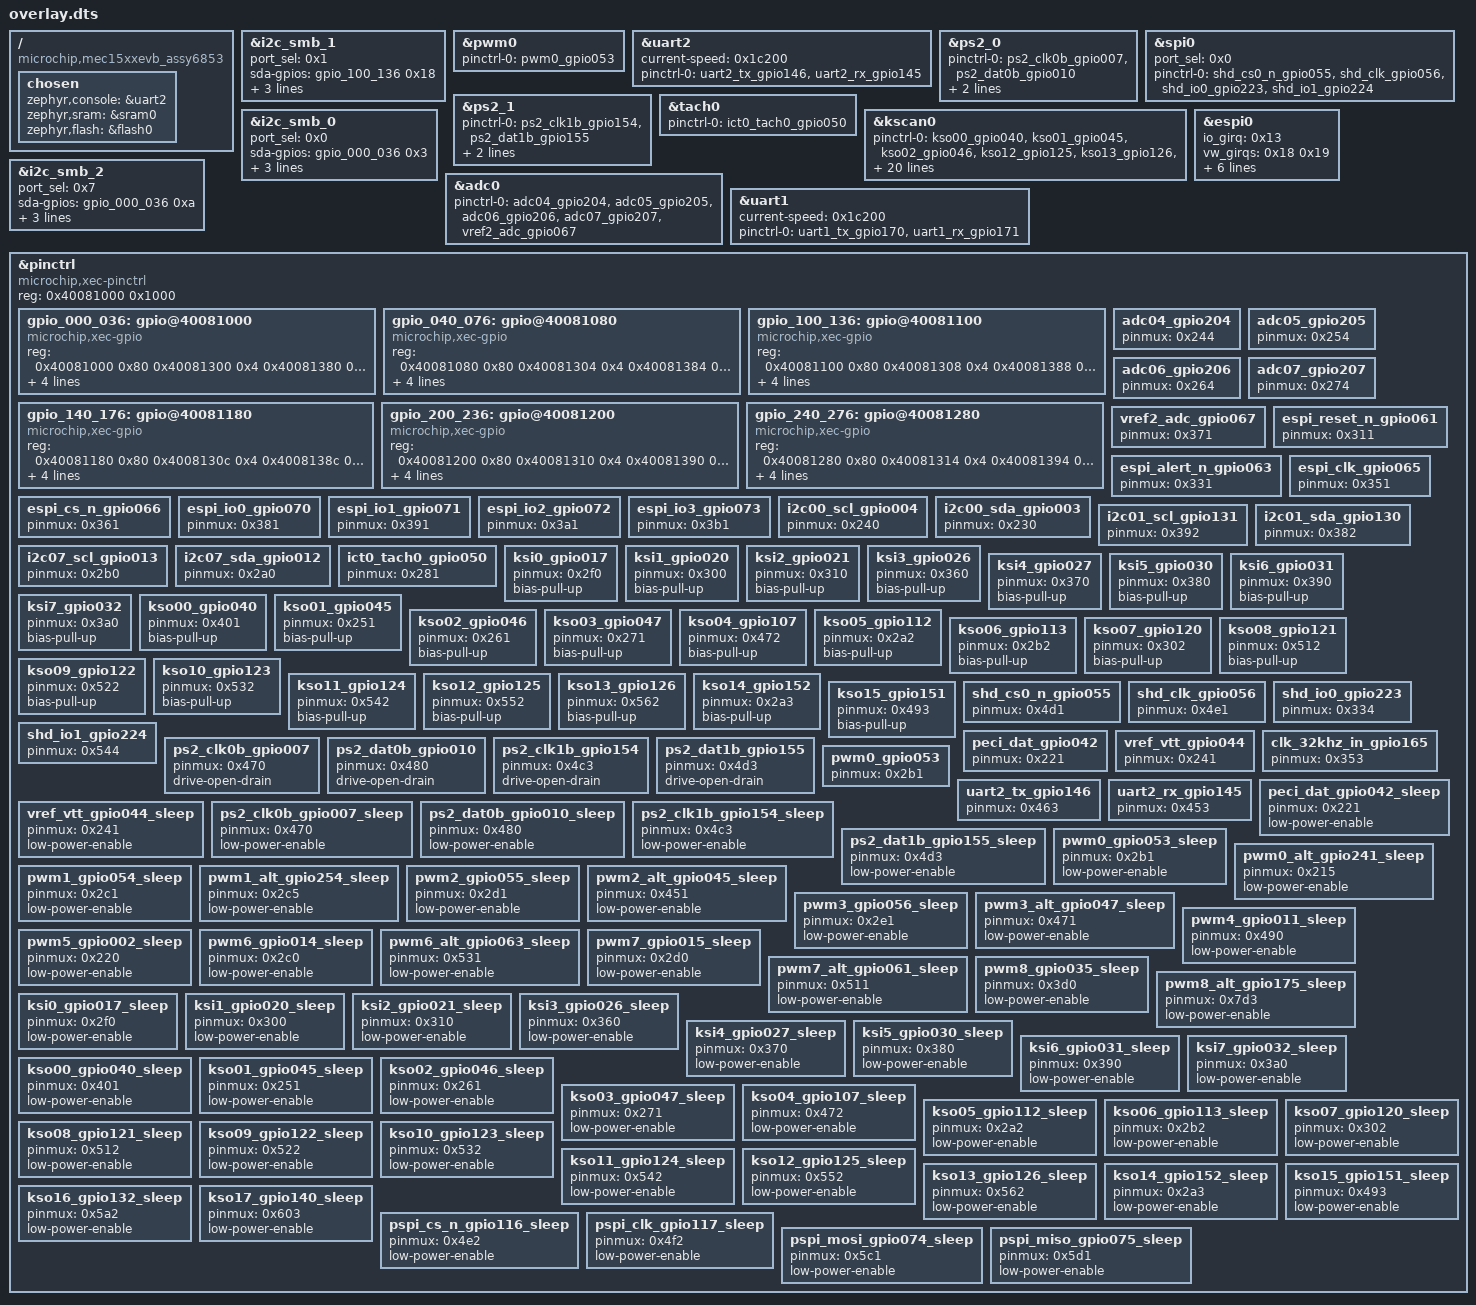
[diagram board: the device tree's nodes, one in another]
/ {
	compatible = "microchip,mec15xxevb_assy6853", "microchip,mec1501hsz";
	chosen {
		zephyr,console = &uart2;
		zephyr,sram = &sram0;
		zephyr,flash = &flash0;
	};
};
&i2c_smb_1{
	status = "okay";
	port_sel = < 0x1 >;
	sda-gpios = < &gpio_100_136 0x18 0x0 >;
	scl-gpios = < &gpio_100_136 0x19 0x0 >;
	pinctrl-0 = < &i2c01_scl_gpio131 &i2c01_sda_gpio130 >;
	pinctrl-names = "default";
};
&pwm0{
	status = "okay";
	pinctrl-0 = < &pwm0_gpio053 >;
	pinctrl-names = "default";
};
&uart2{
	current-speed = < 0x1c200 >;
	status = "okay";
	pinctrl-0 = < &uart2_tx_gpio146 &uart2_rx_gpio145 >;
	pinctrl-names = "default";
};
&ps2_0{
	status = "okay";
	pinctrl-0 = < &ps2_clk0b_gpio007 &ps2_dat0b_gpio010 >;
	pinctrl-1 = < &ps2_clk0b_gpio007_sleep &ps2_dat0b_gpio010_sleep >;
	pinctrl-names = "default", "sleep";
};
&spi0{
	status = "okay";
	port_sel = < 0x0 >;
	pinctrl-0 = < &shd_cs0_n_gpio055 &shd_clk_gpio056 &shd_io0_gpio223 &shd_io1_gpio224 >;
	pinctrl-names = "default";
};
&ps2_1{
	status = "okay";
	pinctrl-0 = < &ps2_clk1b_gpio154 &ps2_dat1b_gpio155 >;
	pinctrl-1 = < &ps2_clk1b_gpio154_sleep &ps2_dat1b_gpio155_sleep >;
	pinctrl-names = "default", "sleep";
};
&tach0{
	status = "okay";
	pinctrl-0 = < &ict0_tach0_gpio050 >;
	pinctrl-names = "default";
};
&i2c_smb_0{
	status = "okay";
	port_sel = < 0x0 >;
	sda-gpios = < &gpio_000_036 0x3 0x0 >;
	scl-gpios = < &gpio_000_036 0x4 0x0 >;
	pinctrl-0 = < &i2c00_scl_gpio004 &i2c00_sda_gpio003 >;
	pinctrl-names = "default";
};
&kscan0{
	status = "okay";
	pinctrl-0 = < &kso00_gpio040 &kso01_gpio045 &kso02_gpio046 &kso12_gpio125 &kso13_gpio126 &kso03_gpio047 &kso04_gpio107 &kso05_gpio112 &kso06_gpio113 &kso14_gpio152 &kso15_gpio151 &kso07_gpio120 &kso08_gpio121 &kso09_gpio122 &kso10_gpio123 &kso11_gpio124 &ksi0_gpio017 &ksi1_gpio020 &ksi2_gpio021 &ksi3_gpio026 &ksi4_gpio027 &ksi5_gpio030 &ksi6_gpio031 &ksi7_gpio032 >;
	pinctrl-1 = < &kso00_gpio040_sleep &kso01_gpio045_sleep &kso02_gpio046_sleep &kso12_gpio125_sleep &kso13_gpio126_sleep &kso03_gpio047_sleep &kso04_gpio107_sleep &kso05_gpio112_sleep &kso06_gpio113_sleep &kso14_gpio152_sleep &kso15_gpio151_sleep &kso07_gpio120_sleep &kso08_gpio121_sleep &kso09_gpio122_sleep &kso10_gpio123_sleep &kso11_gpio124_sleep &ksi0_gpio017_sleep &ksi1_gpio020_sleep &ksi2_gpio021_sleep &ksi3_gpio026_sleep &ksi4_gpio027_sleep &ksi5_gpio030_sleep &ksi6_gpio031_sleep &ksi7_gpio032_sleep >;
	pinctrl-names = "default", "sleep";
};
&espi0{
	status = "okay";
	io_girq = < 0x13 >;
	vw_girqs = < 0x18 0x19 >;
	pc_girq = < 0xf >;
	pinctrl-0 = < &espi_reset_n_gpio061 &espi_cs_n_gpio066 &espi_alert_n_gpio063 &espi_clk_gpio065 &espi_io0_gpio070 &espi_io1_gpio071 &espi_io2_gpio072 &espi_io3_gpio073 >;
	pinctrl-names = "default";
};
&adc0{
	status = "okay";
	pinctrl-0 = < &adc04_gpio204 &adc05_gpio205 &adc06_gpio206 &adc07_gpio207 &vref2_adc_gpio067 >;
	pinctrl-names = "default";
};
&i2c_smb_2{
	status = "okay";
	port_sel = < 0x7 >;
	sda-gpios = < &gpio_000_036 0xa 0x0 >;
	scl-gpios = < &gpio_000_036 0xb 0x0 >;
	pinctrl-0 = < &i2c07_scl_gpio013 &i2c07_sda_gpio012 >;
	pinctrl-names = "default";
};
&uart1{
	current-speed = < 0x1c200 >;
	status = "okay";
	pinctrl-0 = < &uart1_tx_gpio170 &uart1_rx_gpio171 >;
	pinctrl-names = "default";
};
&pinctrl{
	compatible = "microchip,xec-pinctrl";
	#address-cells = < 0x1 >;
	#size-cells = < 0x1 >;
	reg = < 0x40081000 0x1000 >;
	gpio_000_036: gpio@40081000 {
		compatible = "microchip,xec-gpio";
		reg = < 0x40081000 0x80 0x40081300 0x4 0x40081380 0x4 0x400813fc 0x4 >;
		interrupts = < 0x3 0x2 >;
		gpio-controller;
		port-id = < 0x0 >;
		girq-id = < 0xb >;
		#gpio-cells = < 0x2 >;
	};
	gpio_040_076: gpio@40081080 {
		compatible = "microchip,xec-gpio";
		reg = < 0x40081080 0x80 0x40081304 0x4 0x40081384 0x4 0x400813f8 0x4 >;
		interrupts = < 0x2 0x2 >;
		gpio-controller;
		port-id = < 0x1 >;
		girq-id = < 0xa >;
		#gpio-cells = < 0x2 >;
	};
	gpio_100_136: gpio@40081100 {
		compatible = "microchip,xec-gpio";
		reg = < 0x40081100 0x80 0x40081308 0x4 0x40081388 0x4 0x400813f4 0x4 >;
		gpio-controller;
		interrupts = < 0x1 0x2 >;
		port-id = < 0x2 >;
		girq-id = < 0x9 >;
		#gpio-cells = < 0x2 >;
	};
	gpio_140_176: gpio@40081180 {
		compatible = "microchip,xec-gpio";
		reg = < 0x40081180 0x80 0x4008130c 0x4 0x4008138c 0x4 0x400813f0 0x4 >;
		gpio-controller;
		interrupts = < 0x0 0x2 >;
		port-id = < 0x3 >;
		girq-id = < 0x8 >;
		#gpio-cells = < 0x2 >;
	};
	gpio_200_236: gpio@40081200 {
		compatible = "microchip,xec-gpio";
		reg = < 0x40081200 0x80 0x40081310 0x4 0x40081390 0x4 0x400813ec 0x4 >;
		gpio-controller;
		interrupts = < 0x4 0x2 >;
		port-id = < 0x4 >;
		girq-id = < 0xc >;
		#gpio-cells = < 0x2 >;
	};
	gpio_240_276: gpio@40081280 {
		compatible = "microchip,xec-gpio";
		reg = < 0x40081280 0x80 0x40081314 0x4 0x40081394 0x4 0x400813e8 0x4 >;
		gpio-controller;
		interrupts = < 0x11 0x2 >;
		port-id = < 0x5 >;
		girq-id = < 0x1a >;
		#gpio-cells = < 0x2 >;
	};
	adc04_gpio204: adc04_gpio204 {
		pinmux = < 0x244 >;
	};
	adc05_gpio205: adc05_gpio205 {
		pinmux = < 0x254 >;
	};
	adc06_gpio206: adc06_gpio206 {
		pinmux = < 0x264 >;
	};
	adc07_gpio207: adc07_gpio207 {
		pinmux = < 0x274 >;
	};
	vref2_adc_gpio067: vref2_adc_gpio067 {
		pinmux = < 0x371 >;
	};
	espi_reset_n_gpio061: espi_reset_n_gpio061 {
		pinmux = < 0x311 >;
	};
	espi_alert_n_gpio063: espi_alert_n_gpio063 {
		pinmux = < 0x331 >;
	};
	espi_clk_gpio065: espi_clk_gpio065 {
		pinmux = < 0x351 >;
	};
	espi_cs_n_gpio066: espi_cs_n_gpio066 {
		pinmux = < 0x361 >;
	};
	espi_io0_gpio070: espi_io0_gpio070 {
		pinmux = < 0x381 >;
	};
	espi_io1_gpio071: espi_io1_gpio071 {
		pinmux = < 0x391 >;
	};
	espi_io2_gpio072: espi_io2_gpio072 {
		pinmux = < 0x3a1 >;
	};
	espi_io3_gpio073: espi_io3_gpio073 {
		pinmux = < 0x3b1 >;
	};
	i2c00_scl_gpio004: i2c00_scl_gpio004 {
		pinmux = < 0x240 >;
	};
	i2c00_sda_gpio003: i2c00_sda_gpio003 {
		pinmux = < 0x230 >;
	};
	i2c01_scl_gpio131: i2c01_scl_gpio131 {
		pinmux = < 0x392 >;
	};
	i2c01_sda_gpio130: i2c01_sda_gpio130 {
		pinmux = < 0x382 >;
	};
	i2c07_scl_gpio013: i2c07_scl_gpio013 {
		pinmux = < 0x2b0 >;
	};
	i2c07_sda_gpio012: i2c07_sda_gpio012 {
		pinmux = < 0x2a0 >;
	};
	ict0_tach0_gpio050: ict0_tach0_gpio050 {
		pinmux = < 0x281 >;
	};
	ksi0_gpio017: ksi0_gpio017 {
		pinmux = < 0x2f0 >;
		bias-pull-up;
	};
	ksi1_gpio020: ksi1_gpio020 {
		pinmux = < 0x300 >;
		bias-pull-up;
	};
	ksi2_gpio021: ksi2_gpio021 {
		pinmux = < 0x310 >;
		bias-pull-up;
	};
	ksi3_gpio026: ksi3_gpio026 {
		pinmux = < 0x360 >;
		bias-pull-up;
	};
	ksi4_gpio027: ksi4_gpio027 {
		pinmux = < 0x370 >;
		bias-pull-up;
	};
	ksi5_gpio030: ksi5_gpio030 {
		pinmux = < 0x380 >;
		bias-pull-up;
	};
	ksi6_gpio031: ksi6_gpio031 {
		pinmux = < 0x390 >;
		bias-pull-up;
	};
	ksi7_gpio032: ksi7_gpio032 {
		pinmux = < 0x3a0 >;
		bias-pull-up;
	};
	kso00_gpio040: kso00_gpio040 {
		pinmux = < 0x401 >;
		bias-pull-up;
	};
	kso01_gpio045: kso01_gpio045 {
		pinmux = < 0x251 >;
		bias-pull-up;
	};
	kso02_gpio046: kso02_gpio046 {
		pinmux = < 0x261 >;
		bias-pull-up;
	};
	kso03_gpio047: kso03_gpio047 {
		pinmux = < 0x271 >;
		bias-pull-up;
	};
	kso04_gpio107: kso04_gpio107 {
		pinmux = < 0x472 >;
		bias-pull-up;
	};
	kso05_gpio112: kso05_gpio112 {
		pinmux = < 0x2a2 >;
		bias-pull-up;
	};
	kso06_gpio113: kso06_gpio113 {
		pinmux = < 0x2b2 >;
		bias-pull-up;
	};
	kso07_gpio120: kso07_gpio120 {
		pinmux = < 0x302 >;
		bias-pull-up;
	};
	kso08_gpio121: kso08_gpio121 {
		pinmux = < 0x512 >;
		bias-pull-up;
	};
	kso09_gpio122: kso09_gpio122 {
		pinmux = < 0x522 >;
		bias-pull-up;
	};
	kso10_gpio123: kso10_gpio123 {
		pinmux = < 0x532 >;
		bias-pull-up;
	};
	kso11_gpio124: kso11_gpio124 {
		pinmux = < 0x542 >;
		bias-pull-up;
	};
	kso12_gpio125: kso12_gpio125 {
		pinmux = < 0x552 >;
		bias-pull-up;
	};
	kso13_gpio126: kso13_gpio126 {
		pinmux = < 0x562 >;
		bias-pull-up;
	};
	kso14_gpio152: kso14_gpio152 {
		pinmux = < 0x2a3 >;
		bias-pull-up;
	};
	kso15_gpio151: kso15_gpio151 {
		pinmux = < 0x493 >;
		bias-pull-up;
	};
	shd_cs0_n_gpio055: shd_cs0_n_gpio055 {
		pinmux = < 0x4d1 >;
	};
	shd_clk_gpio056: shd_clk_gpio056 {
		pinmux = < 0x4e1 >;
	};
	shd_io0_gpio223: shd_io0_gpio223 {
		pinmux = < 0x334 >;
	};
	shd_io1_gpio224: shd_io1_gpio224 {
		pinmux = < 0x544 >;
	};
	peci_dat_gpio042: peci_dat_gpio042 {
		pinmux = < 0x221 >;
	};
	vref_vtt_gpio044: vref_vtt_gpio044 {
		pinmux = < 0x241 >;
	};
	clk_32khz_in_gpio165: clk_32khz_in_gpio165 {
		pinmux = < 0x353 >;
	};
	ps2_clk0b_gpio007: ps2_clk0b_gpio007 {
		pinmux = < 0x470 >;
		drive-open-drain;
	};
	ps2_dat0b_gpio010: ps2_dat0b_gpio010 {
		pinmux = < 0x480 >;
		drive-open-drain;
	};
	ps2_clk1b_gpio154: ps2_clk1b_gpio154 {
		pinmux = < 0x4c3 >;
		drive-open-drain;
	};
	ps2_dat1b_gpio155: ps2_dat1b_gpio155 {
		pinmux = < 0x4d3 >;
		drive-open-drain;
	};
	pwm0_gpio053: pwm0_gpio053 {
		pinmux = < 0x2b1 >;
	};
	uart2_tx_gpio146: uart2_tx_gpio146 {
		pinmux = < 0x463 >;
	};
	uart2_rx_gpio145: uart2_rx_gpio145 {
		pinmux = < 0x453 >;
	};
	peci_dat_gpio042_sleep: peci_dat_gpio042_sleep {
		pinmux = < 0x221 >;
		low-power-enable;
	};
	vref_vtt_gpio044_sleep: vref_vtt_gpio044_sleep {
		pinmux = < 0x241 >;
		low-power-enable;
	};
	ps2_clk0b_gpio007_sleep: ps2_clk0b_gpio007_sleep {
		pinmux = < 0x470 >;
		low-power-enable;
	};
	ps2_dat0b_gpio010_sleep: ps2_dat0b_gpio010_sleep {
		pinmux = < 0x480 >;
		low-power-enable;
	};
	ps2_clk1b_gpio154_sleep: ps2_clk1b_gpio154_sleep {
		pinmux = < 0x4c3 >;
		low-power-enable;
	};
	ps2_dat1b_gpio155_sleep: ps2_dat1b_gpio155_sleep {
		pinmux = < 0x4d3 >;
		low-power-enable;
	};
	pwm0_gpio053_sleep: pwm0_gpio053_sleep {
		pinmux = < 0x2b1 >;
		low-power-enable;
	};
	pwm0_alt_gpio241_sleep: pwm0_alt_gpio241_sleep {
		pinmux = < 0x215 >;
		low-power-enable;
	};
	pwm1_gpio054_sleep: pwm1_gpio054_sleep {
		pinmux = < 0x2c1 >;
		low-power-enable;
	};
	pwm1_alt_gpio254_sleep: pwm1_alt_gpio254_sleep {
		pinmux = < 0x2c5 >;
		low-power-enable;
	};
	pwm2_gpio055_sleep: pwm2_gpio055_sleep {
		pinmux = < 0x2d1 >;
		low-power-enable;
	};
	pwm2_alt_gpio045_sleep: pwm2_alt_gpio045_sleep {
		pinmux = < 0x451 >;
		low-power-enable;
	};
	pwm3_gpio056_sleep: pwm3_gpio056_sleep {
		pinmux = < 0x2e1 >;
		low-power-enable;
	};
	pwm3_alt_gpio047_sleep: pwm3_alt_gpio047_sleep {
		pinmux = < 0x471 >;
		low-power-enable;
	};
	pwm4_gpio011_sleep: pwm4_gpio011_sleep {
		pinmux = < 0x490 >;
		low-power-enable;
	};
	pwm5_gpio002_sleep: pwm5_gpio002_sleep {
		pinmux = < 0x220 >;
		low-power-enable;
	};
	pwm6_gpio014_sleep: pwm6_gpio014_sleep {
		pinmux = < 0x2c0 >;
		low-power-enable;
	};
	pwm6_alt_gpio063_sleep: pwm6_alt_gpio063_sleep {
		pinmux = < 0x531 >;
		low-power-enable;
	};
	pwm7_gpio015_sleep: pwm7_gpio015_sleep {
		pinmux = < 0x2d0 >;
		low-power-enable;
	};
	pwm7_alt_gpio061_sleep: pwm7_alt_gpio061_sleep {
		pinmux = < 0x511 >;
		low-power-enable;
	};
	pwm8_gpio035_sleep: pwm8_gpio035_sleep {
		pinmux = < 0x3d0 >;
		low-power-enable;
	};
	pwm8_alt_gpio175_sleep: pwm8_alt_gpio175_sleep {
		pinmux = < 0x7d3 >;
		low-power-enable;
	};
	ksi0_gpio017_sleep: ksi0_gpio017_sleep {
		pinmux = < 0x2f0 >;
		low-power-enable;
	};
	ksi1_gpio020_sleep: ksi1_gpio020_sleep {
		pinmux = < 0x300 >;
		low-power-enable;
	};
	ksi2_gpio021_sleep: ksi2_gpio021_sleep {
		pinmux = < 0x310 >;
		low-power-enable;
	};
	ksi3_gpio026_sleep: ksi3_gpio026_sleep {
		pinmux = < 0x360 >;
		low-power-enable;
	};
	ksi4_gpio027_sleep: ksi4_gpio027_sleep {
		pinmux = < 0x370 >;
		low-power-enable;
	};
	ksi5_gpio030_sleep: ksi5_gpio030_sleep {
		pinmux = < 0x380 >;
		low-power-enable;
	};
	ksi6_gpio031_sleep: ksi6_gpio031_sleep {
		pinmux = < 0x390 >;
		low-power-enable;
	};
	ksi7_gpio032_sleep: ksi7_gpio032_sleep {
		pinmux = < 0x3a0 >;
		low-power-enable;
	};
	kso00_gpio040_sleep: kso00_gpio040_sleep {
		pinmux = < 0x401 >;
		low-power-enable;
	};
	kso01_gpio045_sleep: kso01_gpio045_sleep {
		pinmux = < 0x251 >;
		low-power-enable;
	};
	kso02_gpio046_sleep: kso02_gpio046_sleep {
		pinmux = < 0x261 >;
		low-power-enable;
	};
	kso03_gpio047_sleep: kso03_gpio047_sleep {
		pinmux = < 0x271 >;
		low-power-enable;
	};
	kso04_gpio107_sleep: kso04_gpio107_sleep {
		pinmux = < 0x472 >;
		low-power-enable;
	};
	kso05_gpio112_sleep: kso05_gpio112_sleep {
		pinmux = < 0x2a2 >;
		low-power-enable;
	};
	kso06_gpio113_sleep: kso06_gpio113_sleep {
		pinmux = < 0x2b2 >;
		low-power-enable;
	};
	kso07_gpio120_sleep: kso07_gpio120_sleep {
		pinmux = < 0x302 >;
		low-power-enable;
	};
	kso08_gpio121_sleep: kso08_gpio121_sleep {
		pinmux = < 0x512 >;
		low-power-enable;
	};
	kso09_gpio122_sleep: kso09_gpio122_sleep {
		pinmux = < 0x522 >;
		low-power-enable;
	};
	kso10_gpio123_sleep: kso10_gpio123_sleep {
		pinmux = < 0x532 >;
		low-power-enable;
	};
	kso11_gpio124_sleep: kso11_gpio124_sleep {
		pinmux = < 0x542 >;
		low-power-enable;
	};
	kso12_gpio125_sleep: kso12_gpio125_sleep {
		pinmux = < 0x552 >;
		low-power-enable;
	};
	kso13_gpio126_sleep: kso13_gpio126_sleep {
		pinmux = < 0x562 >;
		low-power-enable;
	};
	kso14_gpio152_sleep: kso14_gpio152_sleep {
		pinmux = < 0x2a3 >;
		low-power-enable;
	};
	kso15_gpio151_sleep: kso15_gpio151_sleep {
		pinmux = < 0x493 >;
		low-power-enable;
	};
	kso16_gpio132_sleep: kso16_gpio132_sleep {
		pinmux = < 0x5a2 >;
		low-power-enable;
	};
	kso17_gpio140_sleep: kso17_gpio140_sleep {
		pinmux = < 0x603 >;
		low-power-enable;
	};
	pspi_cs_n_gpio116_sleep: pspi_cs_n_gpio116_sleep {
		pinmux = < 0x4e2 >;
		low-power-enable;
	};
	pspi_clk_gpio117_sleep: pspi_clk_gpio117_sleep {
		pinmux = < 0x4f2 >;
		low-power-enable;
	};
	pspi_mosi_gpio074_sleep: pspi_mosi_gpio074_sleep {
		pinmux = < 0x5c1 >;
		low-power-enable;
	};
	pspi_miso_gpio075_sleep: pspi_miso_gpio075_sleep {
		pinmux = < 0x5d1 >;
		low-power-enable;
	};
};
